# AC7840x register map
Vendor: AutoChips; Series: AC78; File version: 1.0
CPU: CM4 r0p1, little endian, MPU, FPU, VTOR, 4 interrupt priority bits
Registers are 32-bit, read-write, reset 0x0 unless marked. A register's access mark holds for its fields unless they carry their own. Offsets are from the block's base; [hi:lo] are bit positions; {n}, {i} and the like mark numbered series.

## PDT0 — Programmable Delay Timer
Base 0x40086000
Same registers: PDT1 0x40086800
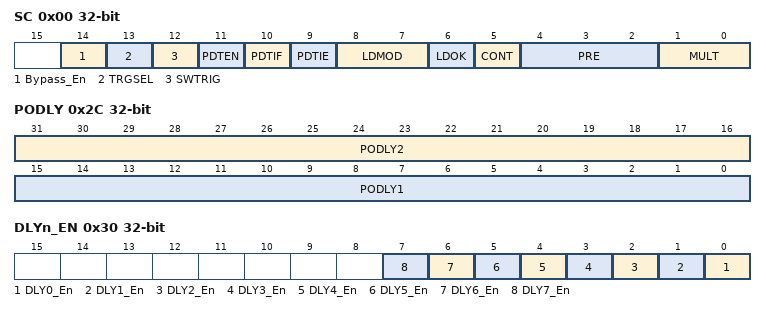
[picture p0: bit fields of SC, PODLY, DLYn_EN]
0x00 SC — PDT Config Register 1
  [14] Bypass_En — Bypass enable
    0=Delay Mode; 1=Bypass of all delay channel,output trigger immediately when receiving a trigger
  [13] TRGSEL — Trigger Input Source Select
    0=Hardware Trigger; 1=Software Trigger
  [12] SWTRIG — Software Trigger
    0=Writing 0 to SWTRIG has no effect; 1=Writing 1 to SWTRIG,Resets and restarts the counter
  [11] PDTEN — PDT Enable
    0=PDT Disable,Counter is Off; 1=PDT Enable
  [10] PDTIF — PDT Interrupt Flag
    0=Write Zero to Clear PDTIF; 1=Writing 1 to PDTIF has no effect
  [9] PDTIE — PDT Interrupt Enable
    0=PDT Interrupt disabled; 1=PDT Interrupt enabled
  [8:7] LDMOD — Load Mode Select
    0=Load After 1 is Written to LDOK; 1=Load When the PDT Counter(CNT) = MODE + 1, After 1 is Written to LDOK; 2=Load When a trigger input event is detected, After 1 is Written to LDOK; 3=Load When the PDT Counter(CNT) = MODE + 1, or a trigger input event is detected, After 1 is Written to LDOK
  [6] LDOK — Load OK
    0=Write 0 To LDOK Has No Effect; 1=Load OK
  [5] CONT — Continuous Mode Enable
    0=PDT operation In One-Shot Mode; 1=PDT operation In Continuous Mode
  [4:2] PRE — Prescaler Divider Select
    0=Counting uses the peripheral clock divided by MULT; 1=Counting uses the peripheral clock divided by 2 * MULT; 2=Counting uses the peripheral clock divided by 4 * MULT; 3=Counting uses the peripheral clock divided by 8 * MULT; 4=Counting uses the peripheral clock divided by 16 * MULT; 5=Counting uses the peripheral clock divided by 32 * MULT; 6=Counting uses the peripheral clock divided by 64 * MULT; 7=Counting uses the peripheral clock divided by 128 * MULT
  [1:0] MULT — Multiplication Factor Select For Prescaler
    0=Multiplication factor is 1; 1=Multiplication factor is 10; 2=Multiplication factor is 20; 3=Multiplication factor is 40
0x04 MOD reset 0xFFFF — PDT Config Register2
  [15:0] MOD — PDT Modulus
{0x8+4i} DLY{i} (i=0..7) — PDT Config Register{i+3}
  [15:0] DLY{i} — PDT Delay{i}
0x28 IDLY reset 0xFFFF — PDT Config Register11
  [15:0] IDLY — PDT Interrupt Delay
0x2C PODLY — PDT Config Register12
  [31:16] PODLY2 — PDT Pulse-Out Delay2
  [15:0] PODLY1 — PDT Pulse-Out Delay1
0x30 DLYn_EN — Delay Enable Register
  [n] DLY{n}_En (n=0..7) — PDT DLY{n} Trigger Enable
    0=PDT DLY{n} Disable; 1=PDT DLY{n} Enable
0x34 POEN — Pulse-Out Enable register
  [0] POEN — PDT Pulse-Out Enable
    0=PDT Pulse-Out disable; 1=PDT Pulse-Out Enable
0x38 CNT — Counter register
  [15:0] CNT ro — PDT Counter

## TIMER_CTRL — Timer Control
Base 0x40011000
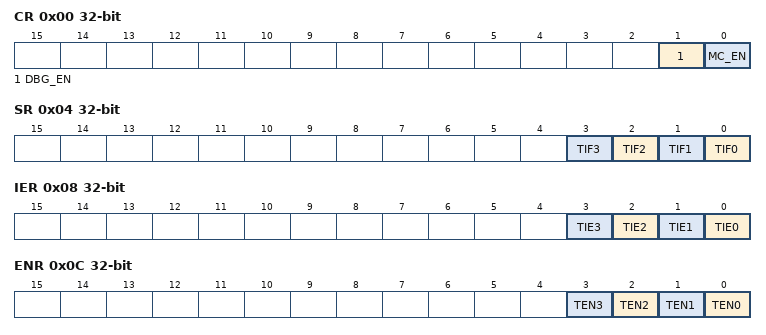
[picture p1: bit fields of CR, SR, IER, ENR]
0x00 CR — Timer Control Regitser
  [1] DBG_EN — Timer Debug Mode Enable
    0=Stop timer channels in Debug mode; 1=Allow timer channels to continue to run in Debug mode
  [0] MC_EN — Module Clock Enable
    0=Disable peripheral clock to timers; 1=Enable peripheral clock to timers
0x04 SR — Timer Status Regitser
  [n] TIF{n} (n=0..3) — Channel {n} Timer Interrupt Flag
    0=Timer{n} interrupt has not occurred; 1=Timer{n} interrupt has occurred
0x08 IER — TIMER Interrupt Enable Register
  [n] TIE{n} (n=0..3) — Channel {n} Timer Interrupt Enable
    0=Channel {n} Timer interrupt disabled; 1=Channel {n} Timer interrupt enabled
0x0C ENR — TIMER Enable Register
  [n] TEN{n} (n=0..3) — Channel {n} Timer Enable bit
    0=Channel {n} Timer disabled; 1=Channel {n} Timer enabled

## TIMER_CHANNEL0
Base 0x40011010
Same registers: TIMER_CHANNEL1 0x40011020, TIMER_CHANNEL2 0x40011030, TIMER_CHANNEL3 0x40011040
0x00 TVAL — Timer Load Value Register
  [31:0] TVAL — Timer Load Value
0x04 CVAL — Timer Current Count Value Register
  [31:0] CVAL — Timer Current Count Value
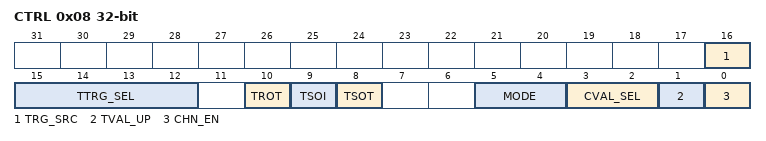
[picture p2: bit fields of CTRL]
0x08 CTRL — Timer channel Control Register
  [16] TRG_SRC — Timer channel Trigger source
    0=Selects external triggers; 1=Selects internal triggers
  [15:12] TTRG_SEL — Timer internal Trigger select
    {v}=trigger source {v} select (v=0..3)
  [10] TROT — Timer Reload On Trigger
    0=Timer will not reload on the selected trigger; 1=Timer will reload on the selected trigger
  [9] TSOI — Timer Stop On Interrupt
    0=The channel timer does not stop after timeout; 1=The channel timer will stop after a timeout
  [8] TSOT — Timer Start On Trigger
    0=Timer starts to increment immediately based on the restart condition(TSOI); 1=Timer starts to increment when a trigger is detected
  [5:4] MODE — Timer Operation Mode
    0=32-bit Periodic Counter; 1=Dual 16-bit Periodic Counter; 2=32-bit Trigger Accumulator; 3=32-bit Trigger Input Capture
  [3:2] CVAL_SEL — Read CVAL precision selection
    0=When BUSCLK/FUNCLK greater than 4; 1=When BUSCLK/FUNCLK greater than 3; 2=When BUSCLK/FUNCLK greater than 1
  [1] TVAL_UP — Timer value update selection
    0=When write,timer value will take effect on timeout occured; 1=When write,timer value will take effect immediately
  [0] CHN_EN — Timer Channel Chain Enable
    0=channel chain is disabled; 1=channel chain is enabled
